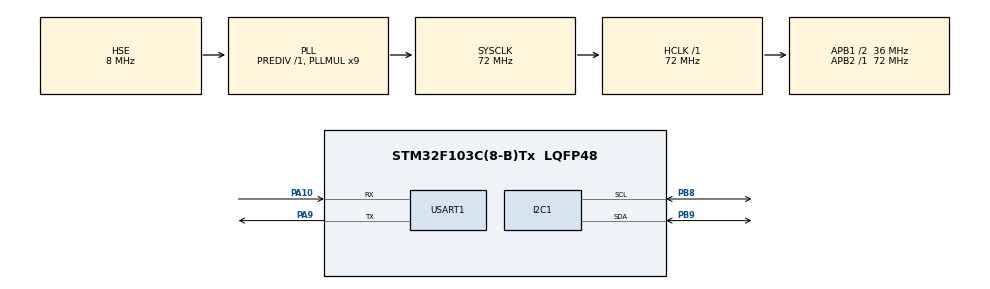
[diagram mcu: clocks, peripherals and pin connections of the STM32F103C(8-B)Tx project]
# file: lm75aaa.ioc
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Mcu.Family=STM32F1
Mcu.Name=STM32F103C(8-B)Tx
Mcu.Package=LQFP48
NVIC.PriorityGroup=NVIC_PRIORITYGROUP_4
PA10.Mode=Asynchronous
PA10.Signal=USART1_RX
PA9.Mode=Asynchronous
PA9.Signal=USART1_TX
PB8.Mode=I2C
PB8.Signal=I2C1_SCL
PB9.Mode=I2C
PB9.Signal=I2C1_SDA
PC14-OSC32_IN.Mode=LSE-External-Oscillator
PC14-OSC32_IN.Signal=RCC_OSC32_IN
PC15-OSC32_OUT.Mode=LSE-External-Oscillator
PC15-OSC32_OUT.Signal=RCC_OSC32_OUT
PD0-OSC_IN.Mode=HSE-External-Oscillator
PD0-OSC_IN.Signal=RCC_OSC_IN
PD1-OSC_OUT.Mode=HSE-External-Oscillator
PD1-OSC_OUT.Signal=RCC_OSC_OUT
ProjectManager.HeapSize=0x200
ProjectManager.StackSize=0x400
ProjectManager.TargetToolchain=MDK-ARM V5.32
RCC.AHBFreq_Value=72000000
RCC.APB1CLKDivider=RCC_HCLK_DIV2
RCC.APB1Freq_Value=36000000
RCC.APB1TimFreq_Value=72000000
RCC.APB2Freq_Value=72000000
RCC.APB2TimFreq_Value=72000000
RCC.HCLKFreq_Value=72000000
RCC.PLLMUL=RCC_PLL_MUL9
RCC.PLLSourceVirtual=RCC_PLLSOURCE_HSE
RCC.SYSCLKFreq_VALUE=72000000
RCC.SYSCLKSource=RCC_SYSCLKSOURCE_PLLCLK
RCC.USBFreq_Value=72000000
USART1.VirtualMode=VM_ASYNC
VP_SYS_VS_ND.Mode=No_Debug
board=custom

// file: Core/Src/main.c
/* USER CODE BEGIN Header */
/**
	******************************************************************************
	* @file           : main.c
	* @brief          : Main program body
	******************************************************************************
	* @attention
	*
	* <h2><center>&copy; Copyright (c) 2021 STMicroelectronics.
	* All rights reserved.</center></h2>
	*
	* This software component is licensed by ST under BSD 3-Clause license,
	* the "License"; You may not use this file except in compliance with the
	* License. You may obtain a copy of the License at:
	*                        opensource.org/licenses/BSD-3-Clause
	*
	******************************************************************************
	*/
/* USER CODE END Header */
#include "main.h"
#include <stdio.h>

I2C_HandleTypeDef hi2c1;

UART_HandleTypeDef huart1;

void SystemClock_Config(void);
static void MX_GPIO_Init(void);
static void MX_I2C1_Init(void);
static void MX_USART1_UART_Init(void);
/* USER CODE BEGIN PFP */
int fputc(int x,FILE *y)
{
				HAL_UART_Transmit(&huart1,(uint8_t*)&x,1,100);
				return 0;
}
/* USER CODE END PFP */

int main(void)
{

	/* MCU Configuration--------------------------------------------------------*/

	/* Reset of all peripherals, Initializes the Flash interface and the Systick. */
	HAL_Init();

	/* Configure the system clock */
	SystemClock_Config();

	/* Initialize all configured peripherals */
	MX_GPIO_Init();
	MX_I2C1_Init();
	MX_USART1_UART_Init();

	/* Infinite loop */
	/* USER CODE BEGIN WHILE */
	uint8_t d2[2];
	int temp;
	float t;
	int set=0;
	while (1)
	{
		/* USER CODE END WHILE */
		HAL_Delay(1000);
		d2[0]=0;d2[1]=0;
		temp=0;t=0;

		printf("\r\n");
						HAL_I2C_Mem_Read(&hi2c1,0x48<<1,0x01,I2C_MEMADD_SIZE_8BIT,d2,1,100);
		temp=d2[0];
		printf("CONF:%x ",d2[0]);
				d2[0]=0;d2[1]=0;
		HAL_I2C_Mem_Read(&hi2c1,0x48<<1,0x00,I2C_MEMADD_SIZE_8BIT,d2,2,100);
		temp=d2[0]<<8|d2[1];
		temp>>=5;
		t=temp*0.125;
		printf("TEMP:%f ",t);
				d2[0]=0;d2[1]=0;
		temp=0;t=0;
		HAL_I2C_Mem_Read(&hi2c1,0x48<<1,0x03,I2C_MEMADD_SIZE_8BIT,d2,2,100);
		temp=d2[0]<<8|d2[1];
		printf("TOS:%x ",temp);
				d2[0]=0;d2[1]=0;
				HAL_I2C_Mem_Read(&hi2c1,0x48<<1,0x02,I2C_MEMADD_SIZE_8BIT,d2,2,100);
		temp=d2[0]<<8|d2[1];
		printf("THYST:%x ",temp);
if(set==0)
{
	set=1;
	printf("set!");
		d2[0]=(uint8_t)0x5A>>1;d2[1]=(uint8_t)0x5A<<7;
		HAL_I2C_Mem_Write(&hi2c1,0x48<<1,0x03,I2C_MEMADD_SIZE_8BIT,d2,2,100);//TOS=45'C
	d2[0]=0;d2[1]=0;

		HAL_I2C_Mem_Write(&hi2c1,0x48<<1,0x02,I2C_MEMADD_SIZE_8BIT,d2,2,100);//THYST=0'C
}
//    HAL_UART_Transmit(&huart1,(uint8_t *)te,5,100);//=============================
	}
}

void SystemClock_Config(void)
{
	RCC_OscInitTypeDef RCC_OscInitStruct = {0};
	RCC_ClkInitTypeDef RCC_ClkInitStruct = {0};

	/** Initializes the RCC Oscillators according to the specified parameters
	* in the RCC_OscInitTypeDef structure.
	*/
	RCC_OscInitStruct.OscillatorType = RCC_OSCILLATORTYPE_HSE;
	RCC_OscInitStruct.HSEState = RCC_HSE_ON;
	RCC_OscInitStruct.HSEPredivValue = RCC_HSE_PREDIV_DIV1;
	RCC_OscInitStruct.HSIState = RCC_HSI_ON;
	RCC_OscInitStruct.PLL.PLLState = RCC_PLL_ON;
	RCC_OscInitStruct.PLL.PLLSource = RCC_PLLSOURCE_HSE;
	RCC_OscInitStruct.PLL.PLLMUL = RCC_PLL_MUL9;
	if (HAL_RCC_OscConfig(&RCC_OscInitStruct) != HAL_OK)
	{
		Error_Handler();
	}
	/** Initializes the CPU, AHB and APB buses clocks
	*/
	RCC_ClkInitStruct.ClockType = RCC_CLOCKTYPE_HCLK|RCC_CLOCKTYPE_SYSCLK
															|RCC_CLOCKTYPE_PCLK1|RCC_CLOCKTYPE_PCLK2;
	RCC_ClkInitStruct.SYSCLKSource = RCC_SYSCLKSOURCE_PLLCLK;
	RCC_ClkInitStruct.AHBCLKDivider = RCC_SYSCLK_DIV1;
	RCC_ClkInitStruct.APB1CLKDivider = RCC_HCLK_DIV2;
	RCC_ClkInitStruct.APB2CLKDivider = RCC_HCLK_DIV1;

	if (HAL_RCC_ClockConfig(&RCC_ClkInitStruct, FLASH_LATENCY_2) != HAL_OK)
	{
		Error_Handler();
	}
}

static void MX_I2C1_Init(void)
{

	hi2c1.Instance = I2C1;
	hi2c1.Init.ClockSpeed = 100000;
	hi2c1.Init.DutyCycle = I2C_DUTYCYCLE_2;
	hi2c1.Init.OwnAddress1 = 0;
	hi2c1.Init.AddressingMode = I2C_ADDRESSINGMODE_7BIT;
	hi2c1.Init.DualAddressMode = I2C_DUALADDRESS_DISABLE;
	hi2c1.Init.OwnAddress2 = 0;
	hi2c1.Init.GeneralCallMode = I2C_GENERALCALL_DISABLE;
	hi2c1.Init.NoStretchMode = I2C_NOSTRETCH_DISABLE;
	if (HAL_I2C_Init(&hi2c1) != HAL_OK)
	{
		Error_Handler();
	}

}

static void MX_USART1_UART_Init(void)
{

	huart1.Instance = USART1;
	huart1.Init.BaudRate = 115200;
	huart1.Init.WordLength = UART_WORDLENGTH_8B;
	huart1.Init.StopBits = UART_STOPBITS_1;
	huart1.Init.Parity = UART_PARITY_NONE;
	huart1.Init.Mode = UART_MODE_TX_RX;
	huart1.Init.HwFlowCtl = UART_HWCONTROL_NONE;
	huart1.Init.OverSampling = UART_OVERSAMPLING_16;
	if (HAL_UART_Init(&huart1) != HAL_OK)
	{
		Error_Handler();
	}

}

static void MX_GPIO_Init(void)
{

	/* GPIO Ports Clock Enable */
	__HAL_RCC_GPIOC_CLK_ENABLE();
	__HAL_RCC_GPIOD_CLK_ENABLE();
	__HAL_RCC_GPIOA_CLK_ENABLE();
	__HAL_RCC_GPIOB_CLK_ENABLE();

}

void Error_Handler(void)
{
	__disable_irq();
	while (1)
	{
	}
}

/************************ (C) COPYRIGHT STMicroelectronics *****END OF FILE****/
